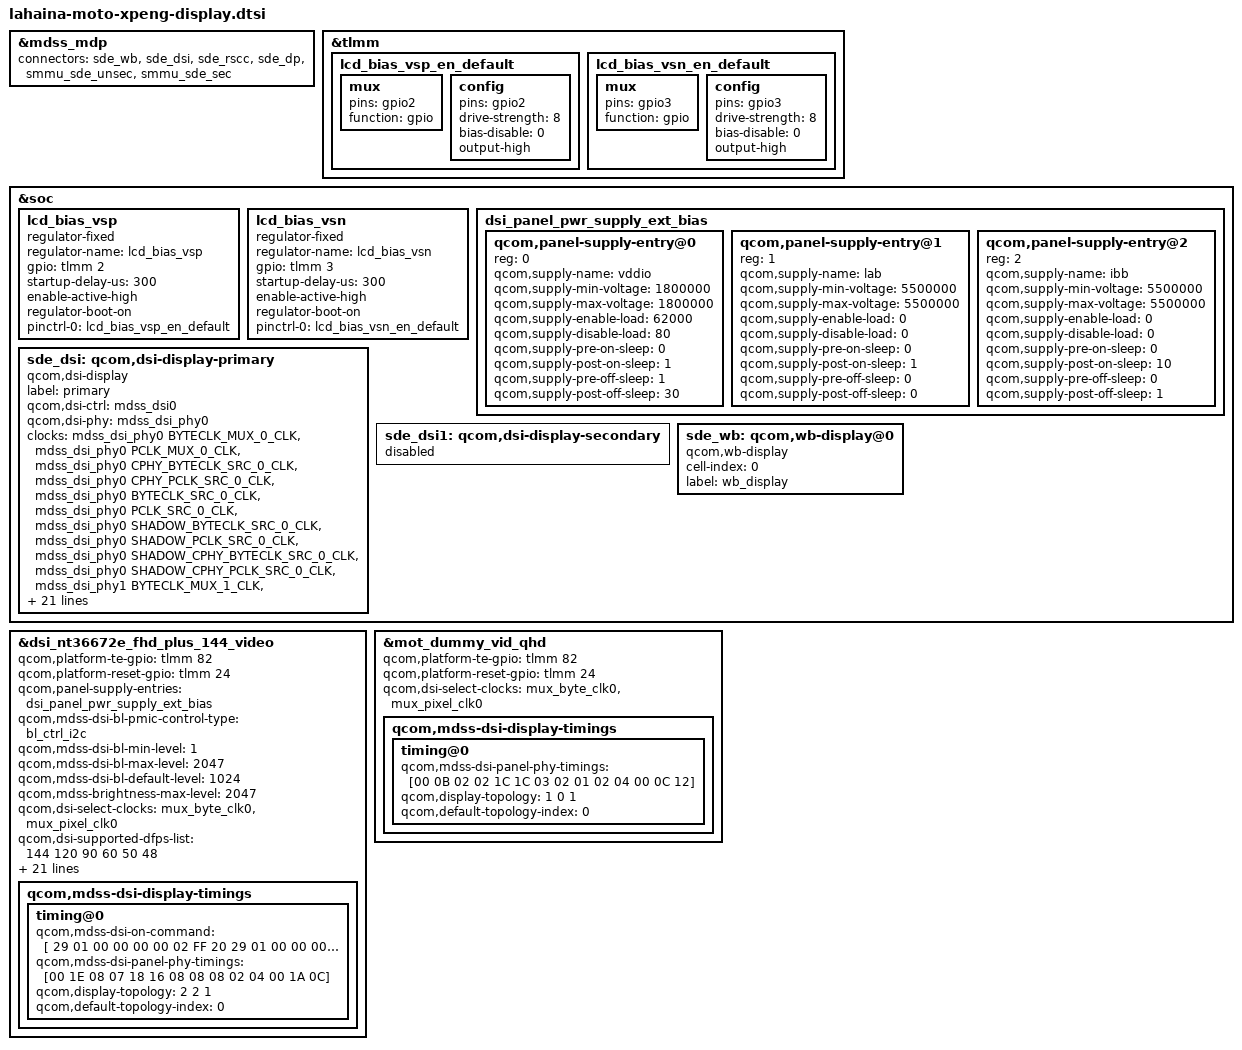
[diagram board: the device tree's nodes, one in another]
/* Copyright (c) 2019, The Linux Foundation. All rights reserved.
 *
 * This program is free software; you can redistribute it and/or modify
 * it under the terms of the GNU General Public License version 2 and
 * only version 2 as published by the Free Software Foundation.
 *
 * This program is distributed in the hope that it will be useful,
 * but WITHOUT ANY WARRANTY; without even the implied warranty of
 * MERCHANTABILITY or FITNESS FOR A PARTICULAR PURPOSE.  See the
 * GNU General Public License for more details.
 */

#include <dt-bindings/clock/mdss-5nm-pll-clk.h>
#include <dt-bindings/clock/qcom,dispcc-lahaina.h>
#include "dsi-panel-mot-tiamma-nt36672e-678-1080p-video-common.dtsi"
#include "dsi-panel-mot-dummy-qhd-video.dtsi"

&mdss_mdp {
	connectors = <&sde_wb &sde_dsi &sde_rscc &sde_dp &smmu_sde_unsec &smmu_sde_sec>;
};


&tlmm {
	lcd_bias_vsp_en_default: lcd_bias_vsp_en_default {
		mux {
			pins = "gpio2";
			function = "gpio";
		};

		config {
			pins = "gpio2";
			drive-strength = <8>;
			bias-disable = <0>;
			output-high;
		};
	};

	lcd_bias_vsn_en_default: lcd_bias_vsn_en_default {
		mux {
			pins = "gpio3";
			function = "gpio";
		};

		config {
			pins = "gpio3";
			drive-strength = <8>;
			bias-disable = <0>;
			output-high;
		};
	};
};

&soc {
	lcd_bias_vsp: lcd_bias_vsp {
		compatible = "regulator-fixed";
		regulator-name = "lcd_bias_vsp";
		gpio = <&tlmm 2 0>;
		startup-delay-us = <300>;
		enable-active-high;
		regulator-boot-on;
		pinctrl-names = "default";
		pinctrl-0 = <&lcd_bias_vsp_en_default>;
	};

	lcd_bias_vsn: lcd_bias_vsn {
		compatible = "regulator-fixed";
		regulator-name = "lcd_bias_vsn";
		gpio = <&tlmm 3 0>;
		startup-delay-us = <300>;
		enable-active-high;
		regulator-boot-on;
		pinctrl-names = "default";
		pinctrl-0 = <&lcd_bias_vsn_en_default>;
	};

        dsi_panel_pwr_supply_ext_bias: dsi_panel_pwr_supply_ext_bias {
                #address-cells = <1>;
                #size-cells = <0>;

                qcom,panel-supply-entry@0 {
                        reg = <0>;
                        qcom,supply-name = "vddio";
                        qcom,supply-min-voltage = <1800000>;
                        qcom,supply-max-voltage = <1800000>;
                        qcom,supply-enable-load = <62000>;
                        qcom,supply-disable-load = <80>;
                        qcom,supply-pre-on-sleep = <0>;
                        qcom,supply-post-on-sleep = <1>;
                        qcom,supply-pre-off-sleep = <1>;
                        qcom,supply-post-off-sleep = <30>;
                };

                qcom,panel-supply-entry@1 {
                        reg = <1>;
                        qcom,supply-name = "lab";
                        qcom,supply-min-voltage = <5500000>;
                        qcom,supply-max-voltage = <5500000>;
                        qcom,supply-enable-load = <0>;
                        qcom,supply-disable-load = <0>;
                        qcom,supply-pre-on-sleep = <0>;
                        qcom,supply-post-on-sleep = <1>;
                        qcom,supply-pre-off-sleep = <0>;
                        qcom,supply-post-off-sleep = <0>;
                };

                qcom,panel-supply-entry@2 {
                        reg = <2>;
                        qcom,supply-name = "ibb";
                        qcom,supply-min-voltage = <5500000>;
                        qcom,supply-max-voltage = <5500000>;
                        qcom,supply-enable-load = <0>;
                        qcom,supply-disable-load = <0>;
                        qcom,supply-pre-on-sleep = <0>;
                        qcom,supply-post-on-sleep = <10>;
                        qcom,supply-pre-off-sleep = <0>;
                        qcom,supply-post-off-sleep = <1>;
                };
        };


	sde_dsi: qcom,dsi-display-primary {
		compatible = "qcom,dsi-display";
		label = "primary";

		qcom,dsi-ctrl = <&mdss_dsi0>;
		qcom,dsi-phy = <&mdss_dsi_phy0>;

		clocks = <&mdss_dsi_phy0 BYTECLK_MUX_0_CLK>,
				 <&mdss_dsi_phy0 PCLK_MUX_0_CLK>,
				 <&mdss_dsi_phy0 CPHY_BYTECLK_SRC_0_CLK>,
				 <&mdss_dsi_phy0 CPHY_PCLK_SRC_0_CLK>,
				 <&mdss_dsi_phy0 BYTECLK_SRC_0_CLK>,
				 <&mdss_dsi_phy0 PCLK_SRC_0_CLK>,
				 <&mdss_dsi_phy0 SHADOW_BYTECLK_SRC_0_CLK>,
				 <&mdss_dsi_phy0 SHADOW_PCLK_SRC_0_CLK>,
				 <&mdss_dsi_phy0 SHADOW_CPHY_BYTECLK_SRC_0_CLK>,
				 <&mdss_dsi_phy0 SHADOW_CPHY_PCLK_SRC_0_CLK>,
				 <&mdss_dsi_phy1 BYTECLK_MUX_1_CLK>,
				 <&mdss_dsi_phy1 PCLK_MUX_1_CLK>,
				 <&mdss_dsi_phy1 CPHY_BYTECLK_SRC_1_CLK>,
				 <&mdss_dsi_phy1 CPHY_PCLK_SRC_1_CLK>,
				 <&mdss_dsi_phy1 BYTECLK_SRC_1_CLK>,
				 <&mdss_dsi_phy1 PCLK_SRC_1_CLK>,
				 <&mdss_dsi_phy1 SHADOW_BYTECLK_SRC_1_CLK>,
				 <&mdss_dsi_phy1 SHADOW_PCLK_SRC_1_CLK>,
				 <&mdss_dsi_phy1 SHADOW_CPHY_BYTECLK_SRC_1_CLK>,
				 <&mdss_dsi_phy1 SHADOW_CPHY_PCLK_SRC_1_CLK>,
				 /*
				  * Currently the dsi clock handles are under the dsi
				  * controller DT node. As soon as the controller probe
				  * finishes, the dispcc sync state can get called before
				  * the dsi_display probe potentially disturbing the clock
				  * votes for cont_splash use case. Hence we are no longer
				  * protected by the component model in this case against the
				  * disp cc sync state getting triggered after the dsi_ctrl
				  * probe. To protect against this incorrect sync state trigger
				  * add this dummy MDP clk vote handle to the dsi_display
				  * DT node. Since the dsi_display driver does not parse
				  * MDP clock nodes, no actual vote shall be added and this
				  * change is done just to satisfy sync state requirements.
				  */
				 <&clock_dispcc DISP_CC_MDSS_MDP_CLK>;
		clock-names = "mux_byte_clk0", "mux_pixel_clk0",
				"cphy_byte_clk0", "cphy_pixel_clk0",
				"src_byte_clk0", "src_pixel_clk0",
				"shadow_byte_clk0", "shadow_pixel_clk0",
				"shadow_cphybyte_clk0", "shadow_cphypixel_clk0",
				"mux_byte_clk1", "mux_pixel_clk1",
				"cphy_byte_clk1", "cphy_pixel_clk1",
				"src_byte_clk1", "src_pixel_clk1",
				"shadow_byte_clk1", "shadow_pixel_clk1",
				"shadow_cphybyte_clk1", "shadow_cphypixel_clk1",
				"mdp_core_clk";

		pinctrl-names = "panel_active", "panel_suspend";
		pinctrl-0 = <&sde_dsi_active &sde_te_active>;
		pinctrl-1 = <&sde_dsi_suspend &sde_te_suspend>;

		qcom,platform-te-gpio = <&tlmm 82 0>;
		qcom,panel-te-source = <0>;

		vddio-supply = <&L12C>;
		lab-supply = <&lcd_bias_vsp>;
		ibb-supply = <&lcd_bias_vsn>;

		qcom,mdp = <&mdss_mdp>;
		qcom,dsi-default-panel = <&dsi_nt36672e_fhd_plus_144_video>;
		qcom,platform-mot-ext-feature-enable;
	};
	sde_dsi1: qcom,dsi-display-secondary {
		status = "disabled";
	};
	sde_wb: qcom,wb-display@0 {
		compatible = "qcom,wb-display";
		cell-index = <0>;
		label = "wb_display";
	};
};

&dsi_nt36672e_fhd_plus_144_video {
        qcom,platform-te-gpio = <&tlmm 82 0>;
        qcom,platform-reset-gpio = <&tlmm 24 0>;


	qcom,panel-supply-entries = <&dsi_panel_pwr_supply_ext_bias>;

	qcom,mdss-dsi-bl-pmic-control-type = "bl_ctrl_i2c";
	qcom,mdss-dsi-bl-min-level = <1>;
	qcom,mdss-dsi-bl-max-level = <2047>;
	qcom,mdss-dsi-bl-default-level = <1024>;
	qcom,mdss-brightness-max-level = <2047>;

	qcom,dsi-select-clocks = "mux_byte_clk0", "mux_pixel_clk0";
	qcom,dsi-supported-dfps-list = <144 120 90 60 50 48>;
	qcom,mdss-dsi-pan-enable-dynamic-fps;
	qcom,mdss-dsi-pan-fps-update = "dfps_immediate_porch_mode_vfp";
	qcom,mdss-dsi-qsync-min-refresh-rate = <48>;

	qcom,esd-check-enabled;
	qcom,mdss-dsi-panel-status-check-mode = "reg_read";
	qcom,mdss-dsi-panel-status-command = [06 01 00 01 00 00 01 0a];
	qcom,mdss-dsi-panel-status-command-state = "dsi_lp_mode";
	qcom,mdss-dsi-panel-status-value = <0x9c>;
	qcom,mdss-dsi-panel-status-read-length = <1>;
	qcom,mdss-dsi-no-panel-on-read-support;

	qcom,mdss-dsi-panel-hdr-enabled;
	qcom,mdss-dsi-panel-hdr-color-primaries = <14950 15800 34065
		15890 13475 35235 6690 2885>;
	qcom,mdss-dsi-panel-peak-brightness = <4200000>;
	qcom,mdss-dsi-panel-blackness-level = <2730>;
	qcom,tp_state_check_enable;
	qcom,mdss-dsi-reset-sequence = <1 5>, <0 1>, <1 10>;

	qcom,mdss-dsi-display-timings {
		timing@0 {
				qcom,mdss-dsi-on-command = [
					29 01 00 00 00 00 02 FF 20
					29 01 00 00 00 00 02 FF 10
					29 01 00 00 00 00 02 FB 01
					29 01 00 00 00 00 02 36 00
					29 01 00 00 00 00 06 3B 03 14 3C 04 04
					29 01 00 00 00 00 02 B0 00
					29 01 00 00 00 00 02 C0 03
					29 01 00 00 00 00 03 C2 1B A0
					29 01 00 00 00 00 02 E9 01

					29 01 00 00 00 00 02 FF E0
					29 01 00 00 00 00 02 FB 01
					29 01 00 00 00 00 02 35 82
					29 01 00 00 00 00 02 85 32

					29 01 00 00 00 00 02 FF F0
					29 01 00 00 00 00 02 FB 01
					29 01 00 00 00 00 02 1C 01
					29 01 00 00 00 00 02 33 01
					29 01 00 00 00 00 02 5A 00
					29 01 00 00 00 00 02 9F 0C

					29 01 00 00 00 00 02 FF D0
					29 01 00 00 00 00 02 FB 01
					29 01 00 00 00 00 02 53 22
					29 01 00 00 00 00 02 54 02

					29 01 00 00 00 00 02 FF C0
					29 01 00 00 00 00 02 FB 01
					29 01 00 00 00 00 02 9C 11
					29 01 00 00 00 00 02 9D 11

					29 01 00 00 00 00 02 FF 10
					29 01 00 00 00 00 02 FB 01
					29 01 00 00 00 00 02 C0 03

					15 01 00 00 00 00 02 FF 23
					15 01 00 00 00 00 02 FB 01
					15 01 00 00 00 00 02 00 80
					15 01 00 00 00 00 02 04 00
					15 01 00 00 00 00 02 05 24
					15 01 00 00 00 00 02 06 01

					15 01 00 00 00 00 02 07 00
					15 01 00 00 00 00 02 08 01
					15 01 00 00 00 00 02 09 00
					15 01 00 00 00 00 02 10 7F
					15 01 00 00 00 00 02 11 01
					15 01 00 00 00 00 02 12 95
					15 01 00 00 00 00 02 15 68
					15 01 00 00 00 00 02 16 0B
					15 01 00 00 00 00 02 19 00
					15 01 00 00 00 00 02 1A 04
					15 01 00 00 00 00 02 1B 08
					15 01 00 00 00 00 02 1C 0C
					15 01 00 00 00 00 02 1D 10
					15 01 00 00 00 00 02 1E 14
					15 01 00 00 00 00 02 1F 18
					15 01 00 00 00 00 02 20 1C
					15 01 00 00 00 00 02 21 20
					15 01 00 00 00 00 02 22 24
					15 01 00 00 00 00 02 23 28
					15 01 00 00 00 00 02 24 2C
					15 01 00 00 00 00 02 25 30
					15 01 00 00 00 00 02 26 34
					15 01 00 00 00 00 02 27 38
					15 01 00 00 00 00 02 28 3C
					15 01 00 00 00 00 02 29 10
					15 01 00 00 00 00 02 2A 20
					15 01 00 00 00 00 02 2B 20
					15 01 00 00 00 00 02 58 FF
					15 01 00 00 00 00 02 59 FD
					15 01 00 00 00 00 02 5A F9
					15 01 00 00 00 00 02 5B F2
					15 01 00 00 00 00 02 5C EB
					15 01 00 00 00 00 02 5D E2
					15 01 00 00 00 00 02 5E D8
					15 01 00 00 00 00 02 5F CE
					15 01 00 00 00 00 02 60 C3
					15 01 00 00 00 00 02 61 B9
					15 01 00 00 00 00 02 62 B0
					15 01 00 00 00 00 02 63 A8
					15 01 00 00 00 00 02 64 A1
					15 01 00 00 00 00 02 65 9A
					15 01 00 00 00 00 02 66 97
					15 01 00 00 00 00 02 67 95

					15 01 00 00 00 00 02 FF 10
					15 01 00 00 00 00 02 FB 01
					39 01 00 00 00 00 03 51 0C CC
					15 01 00 00 00 00 02 53 2C
					15 01 00 00 00 00 02 55 01

					05 01 00 00 50 00 01 11
					05 01 00 00 00 00 01 29
				];

			qcom,mdss-dsi-panel-phy-timings = [00 1E 08 07 18 16 08
				08 08 02 04 00 1A 0C];
			qcom,display-topology = <2 2 1>;
			qcom,default-topology-index = <0>;
		};
	};
};

&mot_dummy_vid_qhd {
	qcom,platform-te-gpio = <&tlmm 82 0>;
	qcom,platform-reset-gpio = <&tlmm 24 0>;

	qcom,dsi-select-clocks = "mux_byte_clk0", "mux_pixel_clk0";
	qcom,mdss-dsi-display-timings {
		timing@0 {
			qcom,mdss-dsi-panel-phy-timings = [00 0B 02 02 1C 1C 03
							02 01 02 04 00 0C 12];
			qcom,display-topology = <1 0 1>;
			qcom,default-topology-index = <0>;
		};
	};
};
